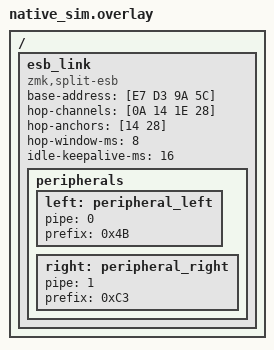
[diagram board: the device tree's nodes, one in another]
/ {
    esb_link {
        compatible = "zmk,split-esb";
        base-address = [E7 D3 9A 5C];
        hop-channels = [0A 14 1E 28];
        hop-anchors = [14 28];
        hop-window-ms = <8>;
        idle-keepalive-ms = <16>;

        peripherals {
            left: peripheral_left {
                pipe = <0>;
                prefix = <0x4B>;
            };

            right: peripheral_right {
                pipe = <1>;
                prefix = <0xC3>;
            };
        };
    };
};
